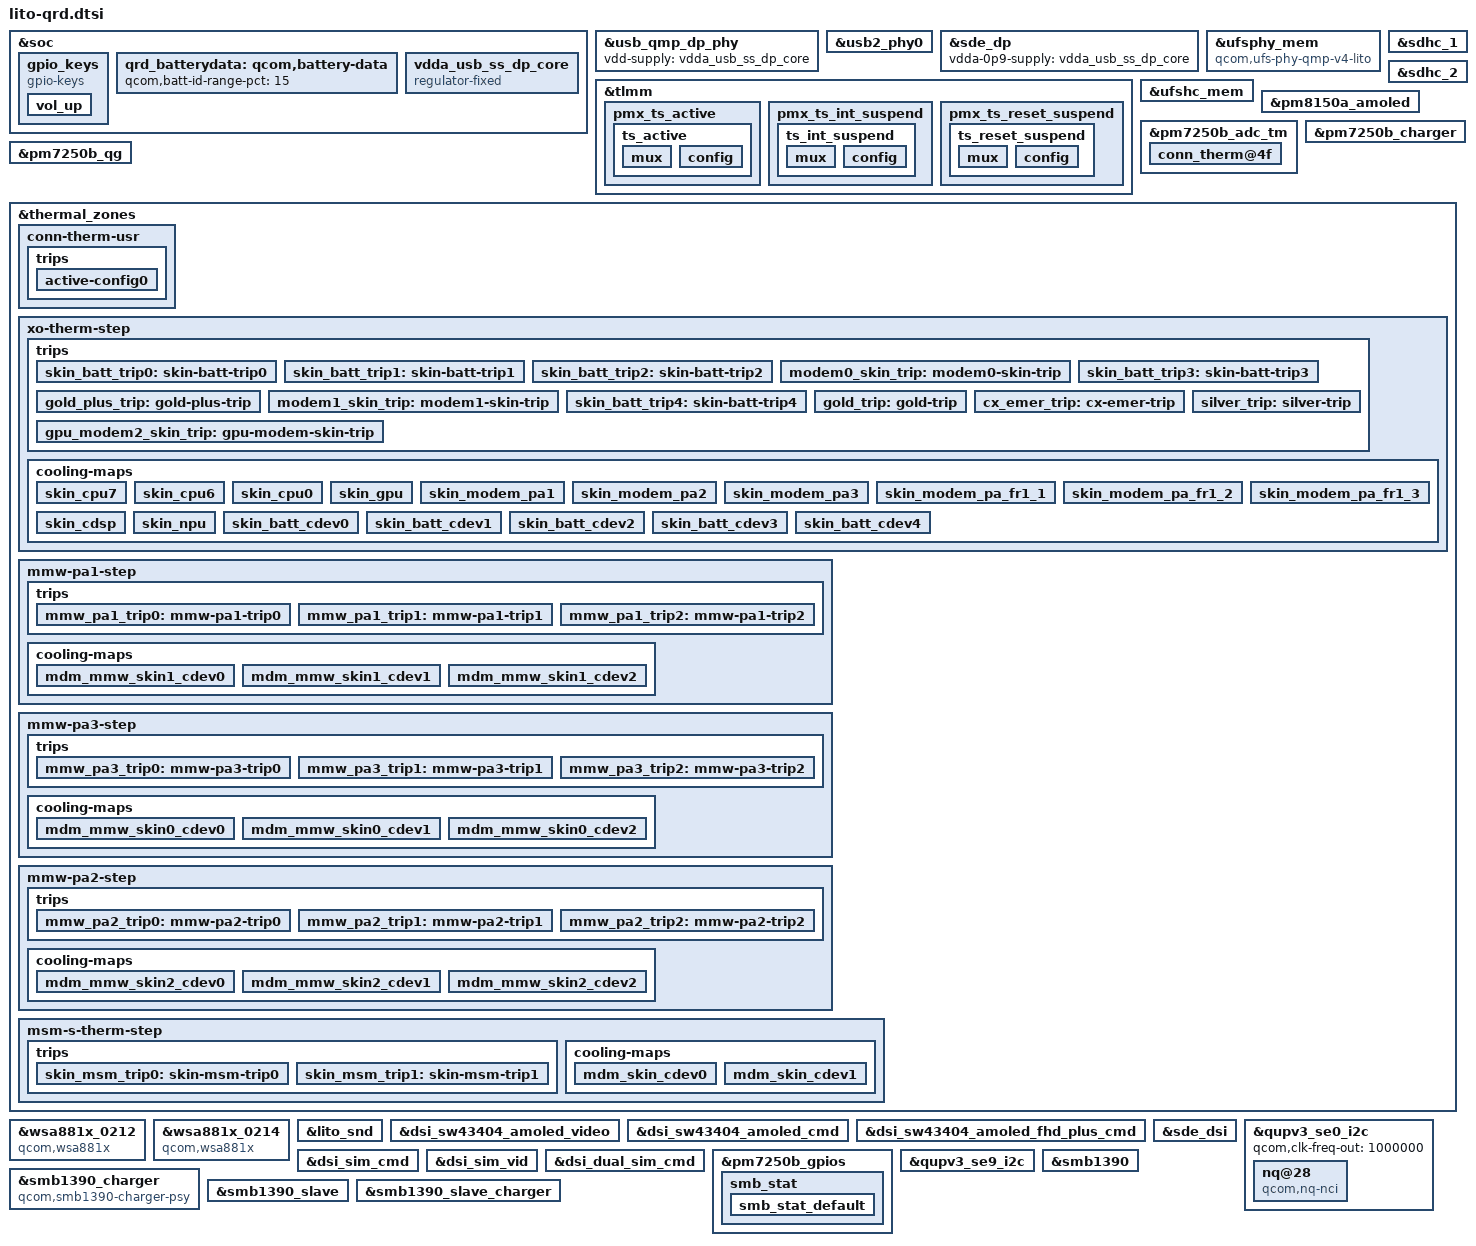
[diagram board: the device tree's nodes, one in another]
#include "lito-pmic-overlay.dtsi"
#include <dt-bindings/gpio/gpio.h>
#include "lito-audio-overlay.dtsi"
#include "lito-thermal-overlay.dtsi"
#include "camera/lito-camera-sensor-qrd.dtsi"
#include "lito-sde-display.dtsi"

&soc {
	gpio_keys {
		compatible = "gpio-keys";
		label = "gpio-keys";

		pinctrl-names = "default";
		pinctrl-0 = <&key_vol_up_default>;

		vol_up {
			label = "volume_up";
			gpios = <&pm8150l_gpios 5 GPIO_ACTIVE_LOW>;
			linux,input-type = <1>;
			linux,code = <KEY_VOLUMEUP>;
			gpio-key,wakeup;
			debounce-interval = <15>;
			linux,can-disable;
		};
	};

	qrd_batterydata: qcom,battery-data {
		qcom,batt-id-range-pct = <15>;
		#include "qg-batterydata-atl466271_3300mAh.dtsi"
	};
	vdda_usb_ss_dp_core: vdda_usb_ss_dp_core {
		compatible = "regulator-fixed";
		regulator-name = "vdd_supply";
		regulator-min-microvolt = <880000>;
		regulator-max-microvolt = <880000>;
		enable-active-high;
		gpio = <&pm8150l_gpios 12 GPIO_ACTIVE_HIGH>;
		pinctrl-names = "default";
		pinctrl-0 = <&usb_eldo13>;
	};
};

&usb_qmp_dp_phy {
	vdd-supply = <&vdda_usb_ss_dp_core>;
};

&usb2_phy0 {
	qcom,param-override-seq = <0x63 0x6c>,
				<0xc8 0x70>,
				<0x17 0x74>;
};

&sde_dp {
	vdda-0p9-supply = <&vdda_usb_ss_dp_core>;
};

&tlmm {
	pmx_ts_active {
		ts_active: ts_active {
			mux {
				pins = "gpio8", "gpio9";
				function = "gpio";
			};

			config {
				pins = "gpio8", "gpio9";
				drive-strength = <8>;
				bias-pull-up;
			};
		};
	};

	pmx_ts_int_suspend {
		ts_int_suspend: ts_int_suspend {
			mux {
				pins = "gpio5";
				function = "gpio";
			};

			config {
				pins = "gpio5";
				drive-strength = <16>;
				bias-disable;
				input-enable;
			};
		};
	};

	pmx_ts_reset_suspend {
		ts_reset_suspend: ts_reset_suspend {
			mux {
				pins = "gpio4";
				function = "gpio";
			};

			config {
				pins = "gpio4";
				drive-strength = <16>;
				bias-disable;
			};
		};
	};

};

&ufsphy_mem {
	compatible = "qcom,ufs-phy-qmp-v4-lito";

	vdda-phy-supply = <&pm8150_l5>;
	vdda-pll-supply = <&pm8150_l9>;
	vdda-phy-max-microamp = <90200>;
	vdda-pll-max-microamp = <19000>;

	status = "ok";
};

&ufshc_mem {
	vdd-hba-supply = <&ufs_phy_gdsc>;
	vdd-hba-fixed-regulator;
	vcc-supply = <&pm8150a_l7>;
	vcc-voltage-level = <2950000 2960000>;
	vccq2-supply = <&pm8150_s4>;
	vcc-max-microamp = <800000>;
	vccq2-max-microamp = <800000>;
	vccq2-min-microamp = <0>;

	qcom,vddp-ref-clk-supply = <&pm8150_l9>;
	qcom,vddp-ref-clk-max-microamp = <100>;
	qcom,vddp-ref-clk-min-microamp = <0>;
	qcom,vddp-ref-clk-min-uV = <1152000>;
	qcom,vddp-ref-clk-max-uV = <1200000>;
	status = "ok";
};

&sdhc_1 {
	vdd-supply = <&pm8150a_l7>;
	qcom,vdd-voltage-level = <2950000 2950000>;
	qcom,vdd-current-level = <0 570000>;

	vdd-io-supply = <&pm8150_s4>;
	qcom,vdd-io-always-on;
	qcom,vdd-io-lpm-sup;
	qcom,vdd-io-voltage-level = <1800000 1800000>;
	qcom,vdd-io-current-level = <0 325000>;

	pinctrl-names = "active", "sleep";
	pinctrl-0 = <&sdc1_clk_on &sdc1_cmd_on &sdc1_data_on
					&sdc1_rclk_on>;
	pinctrl-1 = <&sdc1_clk_off &sdc1_cmd_off &sdc1_data_off
					&sdc1_rclk_off>;

	status = "ok";
};

&sdhc_2 {
	vdd-supply = <&pm8150a_l9>;
	qcom,vdd-voltage-level = <2950000 2950000>;
	qcom,vdd-current-level = <0 800000>;

	vdd-io-supply = <&pm8150a_l6>;
	qcom,vdd-io-voltage-level = <1800000 2950000>;
	qcom,vdd-io-current-level = <0 22000>;

	pinctrl-names = "active", "sleep";
	pinctrl-0 = <&sdc2_clk_on  &sdc2_cmd_on &sdc2_data_on &sdc2_cd_on>;
	pinctrl-1 = <&sdc2_clk_off &sdc2_cmd_off &sdc2_data_off &sdc2_cd_off>;

	cd-gpios = <&tlmm 69 GPIO_ACTIVE_HIGH>;

	status = "ok";
};

&pm8150a_amoled {
	status = "ok";
};

&pm7250b_adc_tm {
	io-channels = <&pm7250b_vadc ADC_AMUX_THM1_PU2>,
			<&pm7250b_vadc ADC_AMUX_THM3_PU2>,
			<&pm7250b_vadc ADC_GPIO2_PU2>,
			<&pm7250b_vadc ADC_GPIO4_PU2>;

	conn_therm@4f {
		reg = <ADC_AMUX_THM3_PU2>;
		qcom,ratiometric;
		qcom,hw-settle-time = <200>;
	};
};

&pm7250b_charger {
	status = "ok";
	io-channels = <&pm7250b_vadc ADC_USB_IN_V_16>,
		      <&pm7250b_vadc ADC_USB_IN_I>,
		      <&pm7250b_vadc ADC_CHG_TEMP>,
		      <&pm7250b_vadc ADC_DIE_TEMP>,
		      <&pm7250b_vadc ADC_AMUX_THM3_PU2>,
		      <&pm7250b_vadc ADC_SBUx>,
		      <&pm7250b_vadc ADC_VPH_PWR>,
		      <&pm7250b_vadc ADC_AMUX_THM1_PU2>;
	io-channel-names = "usb_in_voltage",
			   "usb_in_current",
			   "chg_temp",
			   "die_temp",
			   "conn_temp",
			   "sbux_res",
			   "vph_voltage",
			   "skin_temp";
	qcom,battery-data = <&qrd_batterydata>;
	qcom,sec-charger-config = <1>;
	qcom,auto-recharge-soc = <98>;
	qcom,step-charging-enable;
	qcom,sw-jeita-enable;
	qcom,charger-temp-max = <800>;
	qcom,smb-temp-max = <800>;
	qcom,suspend-input-on-debug-batt;
	qcom,fcc-stepping-enable;
	qcom,fcc-step-delay-ms = <100>;
	qcom,fcc-step-size-ua = <100000>;
	qcom,smb-internal-pull-kohm = <0>;
	qcom,en-skin-therm-mitigation;
	qcom,thermal-mitigation = <8000000 7500000 7000000 6500000 6000000
				5500000 4500000 4000000 3500000 3000000 2500000
				2000000 1500000 1000000 500000>;
};

&pm7250b_qg {
	status = "ok";
	io-channels = <&pm7250b_vadc ADC_BAT_THERM_PU2>,
		      <&pm7250b_vadc ADC_BAT_ID_PU2>;
	io-channel-names = "batt-therm",
			   "batt-id";
	qcom,qg-iterm-ma = <100>;
	qcom,hold-soc-while-full;
	qcom,linearize-soc;
	qcom,cl-feedback-on;
	qcom,tcss-enable;
	qcom,fvss-enable;
	qcom,fvss-vbatt-mv = <3300>;
	qcom,bass-enable;
};

&thermal_zones {
	conn-therm-usr {
		polling-delay-passive = <0>;
		polling-delay = <0>;
		thermal-governor = "user_space";
		thermal-sensors = <&pm7250b_adc_tm ADC_AMUX_THM3_PU2>;
		wake-capable-sensor;
		trips {
			active-config0 {
				temperature = <125000>;
				hysteresis = <1000>;
				type = "passive";
			};
		};
	};

	xo-therm-step {
		polling-delay-passive = <2000>;
		polling-delay = <0>;
		thermal-governor = "step_wise";
		thermal-sensors = <&pm8150_adc_tm ADC_XO_THERM_PU2>;
		wake-capable-sensor;
		trips {
			skin_batt_trip0: skin-batt-trip0 {
				temperature = <42000>;
				hysteresis = <2000>;
				type = "passive";
			};

			skin_batt_trip1: skin-batt-trip1 {
				temperature = <44000>;
				hysteresis = <2000>;
				type = "passive";
			};

			skin_batt_trip2: skin-batt-trip2 {
				temperature = <48000>;
				hysteresis = <4000>;
				type = "passive";
			};

			modem0_skin_trip: modem0-skin-trip {
				temperature = <50000>;
				hysteresis = <4000>;
				type = "passive";
			};

			skin_batt_trip3: skin-batt-trip3 {
				temperature = <50000>;
				hysteresis = <2000>;
				type = "passive";
			};

			gold_plus_trip: gold-plus-trip {
				temperature = <50000>;
				hysteresis = <0>;
				type = "passive";
			};

			modem1_skin_trip: modem1-skin-trip {
				temperature = <52000>;
				hysteresis = <4000>;
				type = "passive";
			};

			skin_batt_trip4: skin-batt-trip4 {
				temperature = <52000>;
				hysteresis = <2000>;
				type = "passive";
			};

			gold_trip: gold-trip {
				temperature = <52000>;
				hysteresis = <0>;
				type = "passive";
			};

			cx_emer_trip: cx-emer-trip {
				temperature = <54000>;
				hysteresis = <6000>;
				type = "passive";
			};

			silver_trip: silver-trip {
				temperature = <54000>;
				hysteresis = <0>;
				type = "passive";
			};

			gpu_modem2_skin_trip: gpu-modem-skin-trip {
				temperature = <56000>;
				hysteresis = <4000>;
				type = "passive";
			};
		};

		cooling-maps {
			skin_cpu7 {
				trip = <&gold_plus_trip>;
					/* throttle from fmax to 1516800KHz */
				cooling-device =
					<&CPU7 THERMAL_NO_LIMIT
						(THERMAL_MAX_LIMIT-3)>;
			};

			skin_cpu6 {
				trip = <&gold_trip>;
					/* throttle from fmax to 1478400KHz */
				cooling-device =
					<&CPU6 THERMAL_NO_LIMIT
						(THERMAL_MAX_LIMIT-3)>;
			};

			skin_cpu0 {
				trip = <&silver_trip>;
					/* throttle from fmax to 1459200KHz */
				cooling-device = <&CPU0 THERMAL_NO_LIMIT
						(THERMAL_MAX_LIMIT-5)>;
			};

			skin_gpu {
				trip = <&gpu_modem2_skin_trip>;
				cooling-device = <&msm_gpu (THERMAL_MAX_LIMIT-1)
						(THERMAL_MAX_LIMIT-1)>;
			};

			skin_modem_pa1 {
				trip = <&modem0_skin_trip>;
				cooling-device = <&modem_pa 1 1>;
			};

			skin_modem_pa2 {
				trip = <&modem1_skin_trip>;
				cooling-device = <&modem_pa 2 2>;
			};

			skin_modem_pa3 {
				trip = <&gpu_modem2_skin_trip>;
				cooling-device = <&modem_pa 3 3>;
			};

			skin_modem_pa_fr1_1 {
				trip = <&modem0_skin_trip>;
				cooling-device = <&modem_pa_fr1 1 1>;
			};

			skin_modem_pa_fr1_2 {
				trip = <&modem1_skin_trip>;
				cooling-device = <&modem_pa_fr1 2 2>;
			};

			skin_modem_pa_fr1_3 {
				trip = <&gpu_modem2_skin_trip>;
				cooling-device = <&modem_pa_fr1 3 3>;
			};

			skin_cdsp {
				trip = <&cx_emer_trip>;
				cooling-device = <&msm_cdsp_rm 3 3>;
			};

			skin_npu {
				trip = <&cx_emer_trip>;
				cooling-device = <&msm_npu THERMAL_MAX_LIMIT
						THERMAL_MAX_LIMIT>;
			};

			skin_batt_cdev0 {
				trip = <&skin_batt_trip0>;
				cooling-device = <&pm7250b_charger 1 1>;
			};

			skin_batt_cdev1 {
				trip = <&skin_batt_trip1>;
				cooling-device = <&pm7250b_charger 5 5>;
			};

			skin_batt_cdev2 {
				trip = <&skin_batt_trip2>;
				cooling-device = <&pm7250b_charger 7 7>;
			};

			skin_batt_cdev3 {
				trip = <&skin_batt_trip3>;
				cooling-device = <&pm7250b_charger 9 9>;
			};

			skin_batt_cdev4 {
				trip = <&skin_batt_trip4>;
				cooling-device = <&pm7250b_charger 11 11>;
			};
		};
	};

	mmw-pa1-step {
		polling-delay-passive = <0>;
		polling-delay = <0>;
		thermal-governor = "step_wise";
		thermal-sensors = <&pm8150l_adc_tm ADC_AMUX_THM3_PU2>;
		wake-capable-sensor;

		trips {
			mmw_pa1_trip0: mmw-pa1-trip0 {
				temperature = <46000>;
				hysteresis = <2000>;
				type = "passive";
			};

			mmw_pa1_trip1: mmw-pa1-trip1 {
				temperature = <49000>;
				hysteresis = <2000>;
				type = "passive";
			};

			mmw_pa1_trip2: mmw-pa1-trip2 {
				temperature = <56000>;
				hysteresis = <6000>;
				type = "passive";
			};
		};

		cooling-maps {
			mdm_mmw_skin1_cdev0 {
				trip = <&mmw_pa1_trip0>;
				cooling-device = <&modem_mmw_skin1 1 1>;
			};

			mdm_mmw_skin1_cdev1 {
				trip = <&mmw_pa1_trip1>;
				cooling-device = <&modem_mmw_skin1 2 2>;
			};

			mdm_mmw_skin1_cdev2 {
				trip = <&mmw_pa1_trip2>;
				cooling-device = <&modem_mmw_skin1 3 3>;
			};
		};
	};

	mmw-pa3-step {
		polling-delay-passive = <0>;
		polling-delay = <0>;
		thermal-governor = "step_wise";
		thermal-sensors = <&pm8150_adc_tm ADC_AMUX_THM2_PU2>;
		wake-capable-sensor;

		trips {
			mmw_pa3_trip0: mmw-pa3-trip0 {
				temperature = <43000>;
				hysteresis = <3000>;
				type = "passive";
			};

			mmw_pa3_trip1: mmw-pa3-trip1 {
				temperature = <45000>;
				hysteresis = <1000>;
				type = "passive";
			};

			mmw_pa3_trip2: mmw-pa3-trip2 {
				temperature = <56000>;
				hysteresis = <6000>;
				type = "passive";
			};
		};

		cooling-maps {
			mdm_mmw_skin0_cdev0 {
				trip = <&mmw_pa3_trip0>;
				cooling-device = <&modem_mmw_skin0 1 1>;
			};

			mdm_mmw_skin0_cdev1 {
				trip = <&mmw_pa3_trip1>;
				cooling-device = <&modem_mmw_skin0 2 2>;
			};

			mdm_mmw_skin0_cdev2 {
				trip = <&mmw_pa3_trip2>;
				cooling-device = <&modem_mmw_skin0 3 3>;
			};
		};
	};

	mmw-pa2-step {
		polling-delay-passive = <0>;
		polling-delay = <0>;
		thermal-governor = "step_wise";
		thermal-sensors = <&pm7250b_adc_tm ADC_GPIO2_PU2>;
		wake-capable-sensor;

		trips {
			mmw_pa2_trip0: mmw-pa2-trip0 {
				temperature = <43000>;
				hysteresis = <3000>;
				type = "passive";
			};

			mmw_pa2_trip1: mmw-pa2-trip1 {
				temperature = <46000>;
				hysteresis = <2000>;
				type = "passive";
			};

			mmw_pa2_trip2: mmw-pa2-trip2 {
				temperature = <56000>;
				hysteresis = <6000>;
				type = "passive";
			};
		};

		cooling-maps {
			mdm_mmw_skin2_cdev0 {
				trip = <&mmw_pa2_trip0>;
				cooling-device = <&modem_mmw_skin2 1 1>;
			};

			mdm_mmw_skin2_cdev1 {
				trip = <&mmw_pa2_trip1>;
				cooling-device = <&modem_mmw_skin2 2 2>;
			};

			mdm_mmw_skin2_cdev2 {
				trip = <&mmw_pa2_trip2>;
				cooling-device = <&modem_mmw_skin2 3 3>;
			};
		};
	};

	msm-s-therm-step {
		polling-delay-passive = <0>;
		polling-delay = <0>;
		thermal-governor = "step_wise";
		thermal-sensors = <&pm8150l_adc_tm ADC_AMUX_THM2_PU2>;
		wake-capable-sensor;

		trips {
			skin_msm_trip0: skin-msm-trip0 {
				temperature = <50000>;
				hysteresis = <4000>;
				type = "passive";
			};

			skin_msm_trip1: skin-msm-trip1 {
				temperature = <56000>;
				hysteresis = <4000>;
				type = "passive";
			};
		};

		cooling-maps {
			mdm_skin_cdev0 {
				trip = <&skin_msm_trip0>;
				cooling-device = <&modem_tj 1 1>;
			};

			mdm_skin_cdev1 {
				trip = <&skin_msm_trip1>;
				cooling-device = <&modem_tj 3 3>;
			};
		};
	};
};

&wsa881x_0212 {
	compatible = "qcom,wsa881x";
	reg = <0x10 0x20170212>;
	qcom,spkr-sd-n-node = <&wsa_spkr_en1>;
};

&wsa881x_0214 {
	compatible = "qcom,wsa881x";
	reg = <0x10 0x21170214>;
	qcom,spkr-sd-n-node = <&wsa_spkr_en1>;
};

&lito_snd {
	qcom,model = "lito-qrd-snd-card";
	qcom,audio-routing =
		"AMIC2", "MIC BIAS2",
		"MIC BIAS2", "Analog Mic2",
		"TX DMIC0", "MIC BIAS3",
		"MIC BIAS3", "Digital Mic0",
		"TX DMIC1", "MIC BIAS3",
		"MIC BIAS3", "Digital Mic1",
		"TX DMIC2", "MIC BIAS1",
		"MIC BIAS1", "Digital Mic2",
		"TX DMIC3", "MIC BIAS1",
		"MIC BIAS1", "Digital Mic3",
		"TX DMIC4", "MIC BIAS4",
		"MIC BIAS4", "Digital Mic4",
		"TX DMIC5", "MIC BIAS4",
		"MIC BIAS4", "Digital Mic5",
		"IN1_HPHL", "HPHL_OUT",
		"IN2_HPHR", "HPHR_OUT",
		"IN3_AUX", "AUX_OUT",
		"TX SWR_ADC0", "ADC1_OUTPUT",
		"TX SWR_ADC1", "ADC2_OUTPUT",
		"TX SWR_ADC2", "ADC3_OUTPUT",
		"TX SWR_ADC3", "ADC4_OUTPUT",
		"TX SWR_DMIC0", "DMIC1_OUTPUT",
		"TX SWR_DMIC1", "DMIC2_OUTPUT",
		"TX SWR_DMIC2", "DMIC3_OUTPUT",
		"TX SWR_DMIC3", "DMIC4_OUTPUT",
		"TX SWR_DMIC4", "DMIC5_OUTPUT",
		"TX SWR_DMIC5", "DMIC6_OUTPUT",
		"TX SWR_DMIC6", "DMIC7_OUTPUT",
		"TX SWR_DMIC7", "DMIC8_OUTPUT",
		"WSA SRC0_INP", "SRC0",
		"WSA_TX DEC0_INP", "TX DEC0 MUX",
		"WSA_TX DEC1_INP", "TX DEC1 MUX",
		"RX_TX DEC0_INP", "TX DEC0 MUX",
		"RX_TX DEC1_INP", "TX DEC1 MUX",
		"RX_TX DEC2_INP", "TX DEC2 MUX",
		"RX_TX DEC3_INP", "TX DEC3 MUX",
		"SpkrRight IN", "WSA_SPK2 OUT",
		"VA_AIF1 CAP", "VA_SWR_CLK",
		"VA_AIF2 CAP", "VA_SWR_CLK",
		"VA_AIF3 CAP", "VA_SWR_CLK",
		"VA MIC BIAS3", "Digital Mic0",
		"VA MIC BIAS3", "Digital Mic1",
		"VA MIC BIAS1", "Digital Mic2",
		"VA MIC BIAS1", "Digital Mic3",
		"VA MIC BIAS4", "Digital Mic4",
		"VA MIC BIAS4", "Digital Mic5",
		"VA DMIC0", "VA MIC BIAS3",
		"VA DMIC1", "VA MIC BIAS3",
		"VA DMIC2", "VA MIC BIAS1",
		"VA DMIC3", "VA MIC BIAS1",
		"VA DMIC4", "VA MIC BIAS4",
		"VA DMIC5", "VA MIC BIAS4",
		"VA SWR_ADC0", "VA_SWR_CLK",
		"VA SWR_ADC1", "VA_SWR_CLK",
		"VA SWR_ADC2", "VA_SWR_CLK",
		"VA SWR_ADC3", "VA_SWR_CLK",
		"VA SWR_MIC0", "VA_SWR_CLK",
		"VA SWR_MIC1", "VA_SWR_CLK",
		"VA SWR_MIC2", "VA_SWR_CLK",
		"VA SWR_MIC3", "VA_SWR_CLK",
		"VA SWR_MIC4", "VA_SWR_CLK",
		"VA SWR_MIC5", "VA_SWR_CLK",
		"VA SWR_MIC6", "VA_SWR_CLK",
		"VA SWR_MIC7", "VA_SWR_CLK",
		"VA SWR_ADC1", "ADC2_OUTPUT",
		"VA SWR_MIC0", "DMIC1_OUTPUT",
		"VA SWR_MIC1", "DMIC2_OUTPUT",
		"VA SWR_MIC0", "DMIC1_OUTPUT",
		"VA SWR_MIC1", "DMIC2_OUTPUT",
		"VA SWR_MIC2", "DMIC3_OUTPUT",
		"VA SWR_MIC3", "DMIC4_OUTPUT",
		"VA SWR_MIC4", "DMIC5_OUTPUT",
		"VA SWR_MIC5", "DMIC6_OUTPUT",
		"VA SWR_MIC6", "DMIC7_OUTPUT",
		"VA SWR_MIC7", "DMIC8_OUTPUT";
	qcom,wsa-max-devs = <1>;
	qcom,wsa-devs = <&wsa881x_0212>, <&wsa881x_0214>;
	qcom,wsa-aux-dev-prefix = "SpkrRight", "SpkrRight";
	qcom,msm-mbhc-usbc-audio-supported = <1>;
	qcom,msm-mbhc-hphl-swh = <1>;
	qcom,msm-mbhc-gnd-swh = <1>;
};

&dsi_sw43404_amoled_video {
	qcom,panel-supply-entries = <&dsi_panel_pwr_supply>;
	qcom,mdss-dsi-bl-pmic-control-type = "bl_ctrl_dcs";
	qcom,mdss-dsi-bl-min-level = <1>;
	qcom,mdss-dsi-bl-max-level = <1023>;
	qcom,mdss-brightness-max-level = <255>;
	qcom,platform-te-gpio = <&tlmm 10 0>;
	qcom,platform-reset-gpio = <&pm8150l_gpios 3 0>;
};

&dsi_sw43404_amoled_cmd {
	qcom,panel-supply-entries = <&dsi_panel_pwr_supply>;
	qcom,mdss-dsi-bl-pmic-control-type = "bl_ctrl_dcs";
	qcom,mdss-dsi-bl-min-level = <1>;
	qcom,mdss-dsi-bl-max-level = <1023>;
	qcom,mdss-brightness-max-level = <255>;
	qcom,platform-te-gpio = <&tlmm 10 0>;
	qcom,platform-reset-gpio = <&pm8150l_gpios 3 0>;
};

&dsi_sw43404_amoled_fhd_plus_cmd {
	qcom,panel-supply-entries = <&dsi_panel_pwr_supply>;
	qcom,mdss-dsi-bl-pmic-control-type = "bl_ctrl_dcs";
	qcom,mdss-dsi-bl-min-level = <1>;
	qcom,mdss-dsi-bl-max-level = <1023>;
	qcom,mdss-brightness-max-level = <255>;
	qcom,platform-te-gpio = <&tlmm 10 0>;
	qcom,platform-reset-gpio = <&pm8150l_gpios 3 0>;
};

&sde_dsi {
	qcom,dsi-default-panel = <&dsi_sw43404_amoled_video>;
};

&qupv3_se0_i2c {
	status = "ok";
	qcom,clk-freq-out = <1000000>;
	#address-cells = <1>;
	#size-cells = <0>;
	nq@28 {
		compatible = "qcom,nq-nci";
		reg = <0x28>;
		qcom,nq-irq = <&tlmm 34 0x00>;
		qcom,nq-ven = <&tlmm 12 0x00>;
		qcom,nq-firm = <&tlmm 35 0x00>;
		qcom,nq-clkreq = <&tlmm 31 0x00>;
		interrupt-parent = <&tlmm>;
		interrupts = <34 0>;
		interrupt-names = "nfc_irq";
		pinctrl-names = "nfc_active", "nfc_suspend";
		pinctrl-0 = <&nfc_int_active &nfc_enable_active
				&nfc_clk_req_active>;
		pinctrl-1 = <&nfc_int_suspend &nfc_enable_suspend
				&nfc_clk_req_suspend>;
	};
};

&dsi_sim_cmd {
	qcom,panel-supply-entries = <&dsi_panel_pwr_supply>;
	qcom,mdss-dsi-bl-pmic-control-type = "bl_ctrl_dcs";
	qcom,platform-reset-gpio = <&pm8150l_gpios 3 0>;
};

&dsi_sim_vid {
	qcom,panel-supply-entries = <&dsi_panel_pwr_supply>;
	qcom,mdss-dsi-bl-pmic-control-type = "bl_ctrl_dcs";
	qcom,platform-reset-gpio = <&pm8150l_gpios 3 0>;
};

&dsi_dual_sim_cmd {
	qcom,panel-supply-entries = <&dsi_panel_pwr_supply>;
	qcom,mdss-dsi-bl-pmic-control-type = "bl_ctrl_dcs";
	qcom,platform-reset-gpio = <&pm8150l_gpios 3 0>;
};

&dsi_dual_sim_cmd {
	qcom,panel-supply-entries = <&dsi_panel_pwr_supply>;
	qcom,mdss-dsi-bl-pmic-control-type = "bl_ctrl_dcs";
	qcom,platform-reset-gpio = <&pm8150l_gpios 3 0>;
};

&pm7250b_gpios {
	smb_stat {
		smb_stat_default: smb_stat_default {
			pins = "gpio6";
			function = "normal";
			input-enable;
			bias-pull-up;
			qcom,pull-up-strength = <PMIC_GPIO_PULL_UP_30>;
			power-source = <0>;
		};
	};
};

&qupv3_se9_i2c {
	status = "ok";
	#include "smb1390.dtsi"
};

&smb1390 {
	/delete-property/ interrupts;
	interrupts = <0x2 0xc5 0x0 IRQ_TYPE_LEVEL_LOW>;
	pinctrl-names = "default";
	pinctrl-0 = <&smb_stat_default>;
	status = "ok";
};

&smb1390_charger {
	compatible = "qcom,smb1390-charger-psy";
	io-channels = <&pm7250b_vadc ADC_AMUX_THM2>;
	io-channel-names = "cp_die_temp";
	qcom,parallel-input-mode = <1>; /* USBIN */
	qcom,parallel-output-mode = <2>; /* VBAT */
	qcom,min-ilim-ua = <750000>;
	status = "ok";
};

&smb1390_slave {
	status = "ok";
};

&smb1390_slave_charger {
	status = "ok";
};
